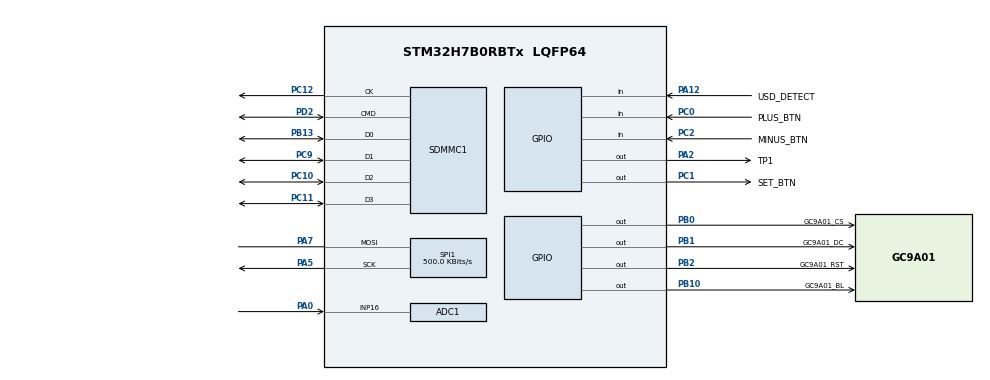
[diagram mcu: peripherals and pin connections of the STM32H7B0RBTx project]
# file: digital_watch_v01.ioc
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ADC1.Channel-0\#ChannelRegularConversion=ADC_CHANNEL_16
ADC1.NbrOfConversionFlag=1
ADC1.OffsetNumber-0\#ChannelRegularConversion=ADC_OFFSET_NONE
ADC1.OffsetSignedSaturation-0\#ChannelRegularConversion=DISABLE
ADC1.Rank-0\#ChannelRegularConversion=1
ADC1.SamplingTime-0\#ChannelRegularConversion=ADC_SAMPLETIME_1CYCLE_5
ADC1.master=1
CORTEX_M7.default_mode_Activation=1
FATFS.BSP.number=1
FATFS0.BSP.STBoard=false
FATFS0.BSP.api=Unknown
FATFS0.BSP.instance=PA12
FATFS0.BSP.ip=GPIO
FATFS0.BSP.mode=Input
FATFS0.BSP.name=Detect_SDIO
FATFS0.BSP.solution=PA12
Mcu.Family=STM32H7
Mcu.Name=STM32H7B0RBTx
Mcu.Package=LQFP64
NVIC.PriorityGroup=NVIC_PRIORITYGROUP_4
PA0.Mode=IN16-Single-Ended
PA0.Signal=ADC1_INP16
PA12.GPIO_Label=USD_DETECT
PA12.Signal=GPIO_Input
PA13.Mode=Serial_Wire
PA13.Signal=DEBUG_JTMS-SWDIO
PA14.Mode=Serial_Wire
PA14.Signal=DEBUG_JTCK-SWCLK
PA2.GPIO_Label=TP1
PA2.Signal=GPIO_Output
PA5.Mode=Simplex_Bidirectional_Master
PA5.Signal=SPI1_SCK
PA7.Mode=Simplex_Bidirectional_Master
PA7.Signal=SPI1_MOSI
PB0.GPIO_Label=GC9A01_CS
PB0.Signal=GPIO_Output
PB1.GPIO_Label=GC9A01_DC
PB1.Signal=GPIO_Output
PB10.GPIO_Label=GC9A01_BL
PB10.PinState=GPIO_PIN_SET
PB10.Signal=GPIO_Output
PB13.GPIO_PuPd=GPIO_PULLUP
PB13.Mode=SD_4_bits_Wide_bus
PB13.Signal=SDMMC1_D0
PB2.GPIO_Label=GC9A01_RST
PB2.PinState=GPIO_PIN_SET
PB2.Signal=GPIO_Output
PB3.Signal=DEBUG_JTDO-SWO
PC0.GPIO_Label=PLUS_BTN
PC0.Signal=GPIO_Input
PC1.GPIO_Label=SET_BTN
PC1.Signal=GPIO_Output
PC10.GPIO_PuPd=GPIO_PULLUP
PC10.Mode=SD_4_bits_Wide_bus
PC10.Signal=SDMMC1_D2
PC11.GPIO_PuPd=GPIO_PULLUP
PC11.Mode=SD_4_bits_Wide_bus
PC11.Signal=SDMMC1_D3
PC12.Mode=SD_4_bits_Wide_bus
PC12.Signal=SDMMC1_CK
PC14-OSC32_IN.Mode=LSE-External-Oscillator
PC14-OSC32_IN.Signal=RCC_OSC32_IN
PC15-OSC32_OUT.Mode=LSE-External-Oscillator
PC15-OSC32_OUT.Signal=RCC_OSC32_OUT
PC2.GPIO_Label=MINUS_BTN
PC2.Signal=GPIO_Input
PC9.GPIO_PuPd=GPIO_PULLUP
PC9.Mode=SD_4_bits_Wide_bus
PC9.Signal=SDMMC1_D1
PD2.GPIO_PuPd=GPIO_PULLUP
PD2.Mode=SD_4_bits_Wide_bus
PD2.Signal=SDMMC1_CMD
PH0-OSC_IN.Mode=HSE-External-Oscillator
PH0-OSC_IN.Signal=RCC_OSC_IN
PH1-OSC_OUT.Mode=HSE-External-Oscillator
PH1-OSC_OUT.Signal=RCC_OSC_OUT
ProjectManager.HeapSize=0x400
ProjectManager.StackSize=0x800
ProjectManager.TargetToolchain=STM32CubeIDE
RCC.ADCFreq_Value=42666666.666666664
RCC.APB1Freq_Value=16000000
RCC.APB2Freq_Value=16000000
RCC.APB3Freq_Value=16000000
RCC.APB4Freq_Value=16000000
RCC.CDCPRE=RCC_SYSCLK_DIV2
RCC.CDPPRE=RCC_APB3_DIV2
RCC.CDPPRE1=RCC_APB1_DIV2
RCC.CDPPRE2=RCC_APB2_DIV2
RCC.CortexFreq_Value=32000000
RCC.DIVM1=4
RCC.DIVM2=4
RCC.DIVN1=8
RCC.DIVN2=8
RCC.DIVP2=3
RCC.DIVQ1=128
RCC.DIVR1=3
RCC.HCLKFreq_Value=32000000
RCC.HSE_VALUE=25000000
RCC.PLL2FRACN=0
RCC.PLLFRACN=0
RCC.RTCClockSelection=RCC_RTCCLKSOURCE_LSE
RCC.SRDPPRE=RCC_APB4_DIV2
RCC.SYSCLKFreq_VALUE=64000000
RCC.SYSCLKSource=RCC_SYSCLKSOURCE_PLLCLK
RCC.USBFreq_Value=1000000
RTC.HourFormat=RTC_HOURFORMAT_12
SPI1.CalculateBaudRate=500.0 KBits/s
SPI1.DataSize=SPI_DATASIZE_8BIT
SPI1.Direction=SPI_DIRECTION_1LINE
SPI1.Mode=SPI_MODE_MASTER
SPI1.VirtualType=VM_MASTER
VP_DMA2D_VS_DMA2D.Mode=DMA2D_Activate
VP_FATFS_VS_SDIO.Mode=SDIO
VP_JPEG_VS_JPEG.Mode=JPEG_Activate
VP_MEMORYMAP_VS_MEMORYMAP.Mode=CurAppReg
VP_RTC_VS_RTC_Activate.Mode=RTC_Enabled
board=custom

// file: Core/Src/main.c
/* USER CODE BEGIN Header */
/**
  ******************************************************************************
  * @file           : main.c
  * @brief          : Main program body
  ******************************************************************************
  * @attention
  *
  * Copyright (c) 2024 STMicroelectronics.
  * All rights reserved.
  *
  * This software is licensed under terms that can be found in the LICENSE file
  * in the root directory of this software component.
  * If no LICENSE file comes with this software, it is provided AS-IS.
  *
  ******************************************************************************
  */
/* USER CODE END Header */
#include "main.h"
#include "fatfs.h"

/* USER CODE BEGIN Includes */
#include "GC9A01.h"
#include "smart_watch.h"
/* USER CODE END Includes */

ADC_HandleTypeDef hadc1;

DMA2D_HandleTypeDef hdma2d;

JPEG_HandleTypeDef hjpeg;

RTC_HandleTypeDef hrtc;

SD_HandleTypeDef hsd1;

SPI_HandleTypeDef hspi1;

void SystemClock_Config(void);
static void MPU_Config(void);
static void MX_GPIO_Init(void);
static void MX_ADC1_Init(void);
static void MX_DMA2D_Init(void);
static void MX_JPEG_Init(void);
static void MX_RTC_Init(void);
static void MX_SDMMC1_SD_Init(void);
static void MX_SPI1_Init(void);

int main(void)
{

  /* MPU Configuration--------------------------------------------------------*/
  MPU_Config();

  /* MCU Configuration--------------------------------------------------------*/

  /* Reset of all peripherals, Initializes the Flash interface and the Systick. */
  HAL_Init();

  /* Configure the system clock */
  SystemClock_Config();

  /* Initialize all configured peripherals */
  MX_GPIO_Init();
  MX_ADC1_Init();
  MX_DMA2D_Init();
  MX_JPEG_Init();
  MX_RTC_Init();
  MX_SDMMC1_SD_Init();
  MX_SPI1_Init();
  MX_FATFS_Init();
  /* USER CODE BEGIN 2 */
  GC9A01_init();
  smart_watch_init();
  smart_watch_process();
  /* USER CODE END 2 */

  /* Infinite loop */
  while (1)
  {

  }
}

void SystemClock_Config(void)
{
  RCC_OscInitTypeDef RCC_OscInitStruct = {0};
  RCC_ClkInitTypeDef RCC_ClkInitStruct = {0};

  /*AXI clock gating */
  RCC->CKGAENR = 0xFFFFFFFF;

  /** Supply configuration update enable
  */
  HAL_PWREx_ConfigSupply(PWR_LDO_SUPPLY);

  /** Configure the main internal regulator output voltage
  */
  __HAL_PWR_VOLTAGESCALING_CONFIG(PWR_REGULATOR_VOLTAGE_SCALE3);

  while(!__HAL_PWR_GET_FLAG(PWR_FLAG_VOSRDY)) {}

  /** Configure LSE Drive Capability
  */
  HAL_PWR_EnableBkUpAccess();
  __HAL_RCC_LSEDRIVE_CONFIG(RCC_LSEDRIVE_LOW);

  /** Initializes the RCC Oscillators according to the specified parameters
  * in the RCC_OscInitTypeDef structure.
  */
  RCC_OscInitStruct.OscillatorType = RCC_OSCILLATORTYPE_HSI|RCC_OSCILLATORTYPE_LSE;
  RCC_OscInitStruct.LSEState = RCC_LSE_ON;
  RCC_OscInitStruct.HSIState = RCC_HSI_DIV1;
  RCC_OscInitStruct.HSICalibrationValue = 64;
  RCC_OscInitStruct.PLL.PLLState = RCC_PLL_ON;
  RCC_OscInitStruct.PLL.PLLSource = RCC_PLLSOURCE_HSI;
  RCC_OscInitStruct.PLL.PLLM = 4;
  RCC_OscInitStruct.PLL.PLLN = 8;
  RCC_OscInitStruct.PLL.PLLP = 2;
  RCC_OscInitStruct.PLL.PLLQ = 128;
  RCC_OscInitStruct.PLL.PLLR = 3;
  RCC_OscInitStruct.PLL.PLLRGE = RCC_PLL1VCIRANGE_3;
  RCC_OscInitStruct.PLL.PLLVCOSEL = RCC_PLL1VCOWIDE;
  RCC_OscInitStruct.PLL.PLLFRACN = 0;
  if (HAL_RCC_OscConfig(&RCC_OscInitStruct) != HAL_OK)
  {
    Error_Handler();
  }

  /** Initializes the CPU, AHB and APB buses clocks
  */
  RCC_ClkInitStruct.ClockType = RCC_CLOCKTYPE_HCLK|RCC_CLOCKTYPE_SYSCLK
                              |RCC_CLOCKTYPE_PCLK1|RCC_CLOCKTYPE_PCLK2
                              |RCC_CLOCKTYPE_D3PCLK1|RCC_CLOCKTYPE_D1PCLK1;
  RCC_ClkInitStruct.SYSCLKSource = RCC_SYSCLKSOURCE_PLLCLK;
  RCC_ClkInitStruct.SYSCLKDivider = RCC_SYSCLK_DIV2;
  RCC_ClkInitStruct.AHBCLKDivider = RCC_HCLK_DIV1;
  RCC_ClkInitStruct.APB3CLKDivider = RCC_APB3_DIV2;
  RCC_ClkInitStruct.APB1CLKDivider = RCC_APB1_DIV2;
  RCC_ClkInitStruct.APB2CLKDivider = RCC_APB2_DIV2;
  RCC_ClkInitStruct.APB4CLKDivider = RCC_APB4_DIV2;

  if (HAL_RCC_ClockConfig(&RCC_ClkInitStruct, FLASH_LATENCY_1) != HAL_OK)
  {
    Error_Handler();
  }
}

static void MX_ADC1_Init(void)
{

  ADC_MultiModeTypeDef multimode = {0};
  ADC_ChannelConfTypeDef sConfig = {0};

  /** Common config
  */
  hadc1.Instance = ADC1;
  hadc1.Init.ClockPrescaler = ADC_CLOCK_ASYNC_DIV1;
  hadc1.Init.Resolution = ADC_RESOLUTION_16B;
  hadc1.Init.ScanConvMode = ADC_SCAN_DISABLE;
  hadc1.Init.EOCSelection = ADC_EOC_SINGLE_CONV;
  hadc1.Init.LowPowerAutoWait = DISABLE;
  hadc1.Init.ContinuousConvMode = DISABLE;
  hadc1.Init.NbrOfConversion = 1;
  hadc1.Init.DiscontinuousConvMode = DISABLE;
  hadc1.Init.ExternalTrigConv = ADC_SOFTWARE_START;
  hadc1.Init.ExternalTrigConvEdge = ADC_EXTERNALTRIGCONVEDGE_NONE;
  hadc1.Init.ConversionDataManagement = ADC_CONVERSIONDATA_DR;
  hadc1.Init.Overrun = ADC_OVR_DATA_PRESERVED;
  hadc1.Init.LeftBitShift = ADC_LEFTBITSHIFT_NONE;
  hadc1.Init.OversamplingMode = DISABLE;
  if (HAL_ADC_Init(&hadc1) != HAL_OK)
  {
    Error_Handler();
  }

  /** Configure the ADC multi-mode
  */
  multimode.Mode = ADC_MODE_INDEPENDENT;
  if (HAL_ADCEx_MultiModeConfigChannel(&hadc1, &multimode) != HAL_OK)
  {
    Error_Handler();
  }

  /** Configure Regular Channel
  */
  sConfig.Channel = ADC_CHANNEL_16;
  sConfig.Rank = ADC_REGULAR_RANK_1;
  sConfig.SamplingTime = ADC_SAMPLETIME_1CYCLE_5;
  sConfig.SingleDiff = ADC_SINGLE_ENDED;
  sConfig.OffsetNumber = ADC_OFFSET_NONE;
  sConfig.Offset = 0;
  sConfig.OffsetSignedSaturation = DISABLE;
  if (HAL_ADC_ConfigChannel(&hadc1, &sConfig) != HAL_OK)
  {
    Error_Handler();
  }

}

static void MX_DMA2D_Init(void)
{

  hdma2d.Instance = DMA2D;
  hdma2d.Init.Mode = DMA2D_M2M;
  hdma2d.Init.ColorMode = DMA2D_OUTPUT_ARGB8888;
  hdma2d.Init.OutputOffset = 0;
  hdma2d.LayerCfg[1].InputOffset = 0;
  hdma2d.LayerCfg[1].InputColorMode = DMA2D_INPUT_ARGB8888;
  hdma2d.LayerCfg[1].AlphaMode = DMA2D_NO_MODIF_ALPHA;
  hdma2d.LayerCfg[1].InputAlpha = 0;
  hdma2d.LayerCfg[1].AlphaInverted = DMA2D_REGULAR_ALPHA;
  hdma2d.LayerCfg[1].RedBlueSwap = DMA2D_RB_REGULAR;
  hdma2d.LayerCfg[1].ChromaSubSampling = DMA2D_NO_CSS;
  if (HAL_DMA2D_Init(&hdma2d) != HAL_OK)
  {
    Error_Handler();
  }
  if (HAL_DMA2D_ConfigLayer(&hdma2d, 1) != HAL_OK)
  {
    Error_Handler();
  }

}

static void MX_JPEG_Init(void)
{

  hjpeg.Instance = JPEG;
  if (HAL_JPEG_Init(&hjpeg) != HAL_OK)
  {
    Error_Handler();
  }

}

static void MX_RTC_Init(void)
{

  /** Initialize RTC Only
  */
  hrtc.Instance = RTC;
  hrtc.Init.HourFormat = RTC_HOURFORMAT_12;
  hrtc.Init.AsynchPrediv = 127;
  hrtc.Init.SynchPrediv = 255;
  hrtc.Init.OutPut = RTC_OUTPUT_DISABLE;
  hrtc.Init.OutPutPolarity = RTC_OUTPUT_POLARITY_HIGH;
  hrtc.Init.OutPutType = RTC_OUTPUT_TYPE_OPENDRAIN;
  hrtc.Init.OutPutRemap = RTC_OUTPUT_REMAP_NONE;
  if (HAL_RTC_Init(&hrtc) != HAL_OK)
  {
    Error_Handler();
  }

}

static void MX_SDMMC1_SD_Init(void)
{

  hsd1.Instance = SDMMC1;
  hsd1.Init.ClockEdge = SDMMC_CLOCK_EDGE_RISING;
  hsd1.Init.ClockPowerSave = SDMMC_CLOCK_POWER_SAVE_DISABLE;
  hsd1.Init.BusWide = SDMMC_BUS_WIDE_4B;
  hsd1.Init.HardwareFlowControl = SDMMC_HARDWARE_FLOW_CONTROL_DISABLE;
  hsd1.Init.ClockDiv = 0;

}

static void MX_SPI1_Init(void)
{

  /* SPI1 parameter configuration*/
  hspi1.Instance = SPI1;
  hspi1.Init.Mode = SPI_MODE_MASTER;
  hspi1.Init.Direction = SPI_DIRECTION_1LINE;
  hspi1.Init.DataSize = SPI_DATASIZE_8BIT;
  hspi1.Init.CLKPolarity = SPI_POLARITY_LOW;
  hspi1.Init.CLKPhase = SPI_PHASE_1EDGE;
  hspi1.Init.NSS = SPI_NSS_SOFT;
  hspi1.Init.BaudRatePrescaler = SPI_BAUDRATEPRESCALER_2;
  hspi1.Init.FirstBit = SPI_FIRSTBIT_MSB;
  hspi1.Init.TIMode = SPI_TIMODE_DISABLE;
  hspi1.Init.CRCCalculation = SPI_CRCCALCULATION_DISABLE;
  hspi1.Init.CRCPolynomial = 0x0;
  hspi1.Init.NSSPMode = SPI_NSS_PULSE_ENABLE;
  hspi1.Init.NSSPolarity = SPI_NSS_POLARITY_LOW;
  hspi1.Init.FifoThreshold = SPI_FIFO_THRESHOLD_01DATA;
  hspi1.Init.TxCRCInitializationPattern = SPI_CRC_INITIALIZATION_ALL_ZERO_PATTERN;
  hspi1.Init.RxCRCInitializationPattern = SPI_CRC_INITIALIZATION_ALL_ZERO_PATTERN;
  hspi1.Init.MasterSSIdleness = SPI_MASTER_SS_IDLENESS_00CYCLE;
  hspi1.Init.MasterInterDataIdleness = SPI_MASTER_INTERDATA_IDLENESS_00CYCLE;
  hspi1.Init.MasterReceiverAutoSusp = SPI_MASTER_RX_AUTOSUSP_DISABLE;
  hspi1.Init.MasterKeepIOState = SPI_MASTER_KEEP_IO_STATE_DISABLE;
  hspi1.Init.IOSwap = SPI_IO_SWAP_DISABLE;
  if (HAL_SPI_Init(&hspi1) != HAL_OK)
  {
    Error_Handler();
  }

}

static void MX_GPIO_Init(void)
{
  GPIO_InitTypeDef GPIO_InitStruct = {0};

  /* GPIO Ports Clock Enable */
  __HAL_RCC_GPIOC_CLK_ENABLE();
  __HAL_RCC_GPIOH_CLK_ENABLE();
  __HAL_RCC_GPIOA_CLK_ENABLE();
  __HAL_RCC_GPIOB_CLK_ENABLE();
  __HAL_RCC_GPIOD_CLK_ENABLE();

  /*Configure GPIO pin Output Level */
  HAL_GPIO_WritePin(SET_BTN_GPIO_Port, SET_BTN_Pin, GPIO_PIN_RESET);

  /*Configure GPIO pin Output Level */
  HAL_GPIO_WritePin(TP1_GPIO_Port, TP1_Pin, GPIO_PIN_RESET);

  /*Configure GPIO pin Output Level */
  HAL_GPIO_WritePin(GPIOB, GC9A01_CS_Pin|GC9A01_DC_Pin, GPIO_PIN_RESET);

  /*Configure GPIO pin Output Level */
  HAL_GPIO_WritePin(GPIOB, GC9A01_RST_Pin|GC9A01_BL_Pin, GPIO_PIN_SET);

  /*Configure GPIO pins : PLUS_BTN_Pin MINUS_BTN_Pin */
  GPIO_InitStruct.Pin = PLUS_BTN_Pin|MINUS_BTN_Pin;
  GPIO_InitStruct.Mode = GPIO_MODE_INPUT;
  GPIO_InitStruct.Pull = GPIO_NOPULL;
  HAL_GPIO_Init(GPIOC, &GPIO_InitStruct);

  /*Configure GPIO pin : SET_BTN_Pin */
  GPIO_InitStruct.Pin = SET_BTN_Pin;
  GPIO_InitStruct.Mode = GPIO_MODE_OUTPUT_PP;
  GPIO_InitStruct.Pull = GPIO_NOPULL;
  GPIO_InitStruct.Speed = GPIO_SPEED_FREQ_LOW;
  HAL_GPIO_Init(SET_BTN_GPIO_Port, &GPIO_InitStruct);

  /*Configure GPIO pin : TP1_Pin */
  GPIO_InitStruct.Pin = TP1_Pin;
  GPIO_InitStruct.Mode = GPIO_MODE_OUTPUT_PP;
  GPIO_InitStruct.Pull = GPIO_NOPULL;
  GPIO_InitStruct.Speed = GPIO_SPEED_FREQ_LOW;
  HAL_GPIO_Init(TP1_GPIO_Port, &GPIO_InitStruct);

  /*Configure GPIO pins : GC9A01_CS_Pin GC9A01_DC_Pin GC9A01_RST_Pin GC9A01_BL_Pin */
  GPIO_InitStruct.Pin = GC9A01_CS_Pin|GC9A01_DC_Pin|GC9A01_RST_Pin|GC9A01_BL_Pin;
  GPIO_InitStruct.Mode = GPIO_MODE_OUTPUT_PP;
  GPIO_InitStruct.Pull = GPIO_NOPULL;
  GPIO_InitStruct.Speed = GPIO_SPEED_FREQ_LOW;
  HAL_GPIO_Init(GPIOB, &GPIO_InitStruct);

  /*Configure GPIO pin : USD_DETECT_Pin */
  GPIO_InitStruct.Pin = USD_DETECT_Pin;
  GPIO_InitStruct.Mode = GPIO_MODE_INPUT;
  GPIO_InitStruct.Pull = GPIO_NOPULL;
  HAL_GPIO_Init(USD_DETECT_GPIO_Port, &GPIO_InitStruct);

}

 /* MPU Configuration */

void MPU_Config(void)
{
  MPU_Region_InitTypeDef MPU_InitStruct = {0};

  /* Disables the MPU */
  HAL_MPU_Disable();

  /** Initializes and configures the Region and the memory to be protected
  */
  MPU_InitStruct.Enable = MPU_REGION_ENABLE;
  MPU_InitStruct.Number = MPU_REGION_NUMBER0;
  MPU_InitStruct.BaseAddress = 0x0;
  MPU_InitStruct.Size = MPU_REGION_SIZE_4GB;
  MPU_InitStruct.SubRegionDisable = 0x87;
  MPU_InitStruct.TypeExtField = MPU_TEX_LEVEL0;
  MPU_InitStruct.AccessPermission = MPU_REGION_NO_ACCESS;
  MPU_InitStruct.DisableExec = MPU_INSTRUCTION_ACCESS_DISABLE;
  MPU_InitStruct.IsShareable = MPU_ACCESS_SHAREABLE;
  MPU_InitStruct.IsCacheable = MPU_ACCESS_NOT_CACHEABLE;
  MPU_InitStruct.IsBufferable = MPU_ACCESS_NOT_BUFFERABLE;

  HAL_MPU_ConfigRegion(&MPU_InitStruct);
  /* Enables the MPU */
  HAL_MPU_Enable(MPU_PRIVILEGED_DEFAULT);

}

void Error_Handler(void)
{
  __disable_irq();
  while (1)
  {
  }
}
